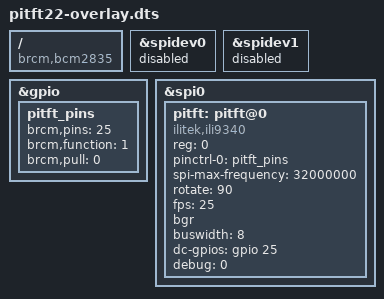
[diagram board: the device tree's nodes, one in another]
/*
 * Device Tree overlay for pitft by Adafruit
 *
 */

/dts-v1/;
/plugin/;

/ {
        compatible = "brcm,bcm2835";

        fragment@0 {
                target = <&spidev0>;
                __overlay__ {
                        status = "disabled";
                };
        };

        fragment@1 {
                target = <&spidev1>;
                __overlay__ {
                        status = "disabled";
                };
        };

        fragment@2 {
                target = <&gpio>;
                __overlay__ {
                        pitft_pins: pitft_pins {
                                brcm,pins = <25>;
                                brcm,function = <1>; /* out */
                                brcm,pull = <0>; /* none */
                        };
                };
        };

        fragment@3 {
                target = <&spi0>;
                __overlay__ {
                        /* needed to avoid dtc warning */
                        #address-cells = <1>;
                        #size-cells = <0>;
                        status = "okay";

                        pitft: pitft@0{
                                compatible = "ilitek,ili9340";
                                reg = <0>;
                                pinctrl-names = "default";
                                pinctrl-0 = <&pitft_pins>;

                                spi-max-frequency = <32000000>;
                                rotate = <90>;
                                fps = <25>;
                                bgr;
                                buswidth = <8>;
                                dc-gpios = <&gpio 25 0>;
                                debug = <0>;
                        };

                };
        };

        __overrides__ {
                speed =   <&pitft>,"spi-max-frequency:0";
                rotate =  <&pitft>,"rotate:0";
                fps =     <&pitft>,"fps:0";
                debug =   <&pitft>,"debug:0";
        };
};
